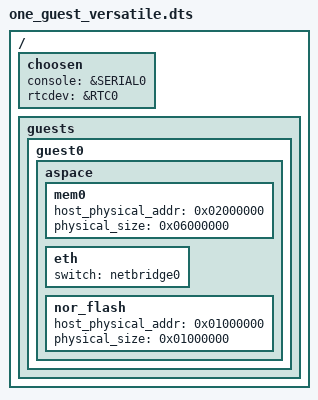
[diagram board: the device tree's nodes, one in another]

/dts-v1/;

/include/ "versatile.dtsi"

/include/ "../../common/guests/one_guest_versatilepb.dtsi"

/ {
	choosen {
		console = &SERIAL0;
		rtcdev = &RTC0;
	};

	guests {
		guest0 {
			aspace {
				mem0 {
					host_physical_addr = <0x02000000>;
					physical_size = <0x06000000>; /* 96 MB */
				};

				eth {
					switch = "netbridge0";
				};

				nor_flash {
					host_physical_addr = <0x01000000>;
					physical_size = <0x01000000>; /* 16 MB */
				};
			};
		};
	};
};
